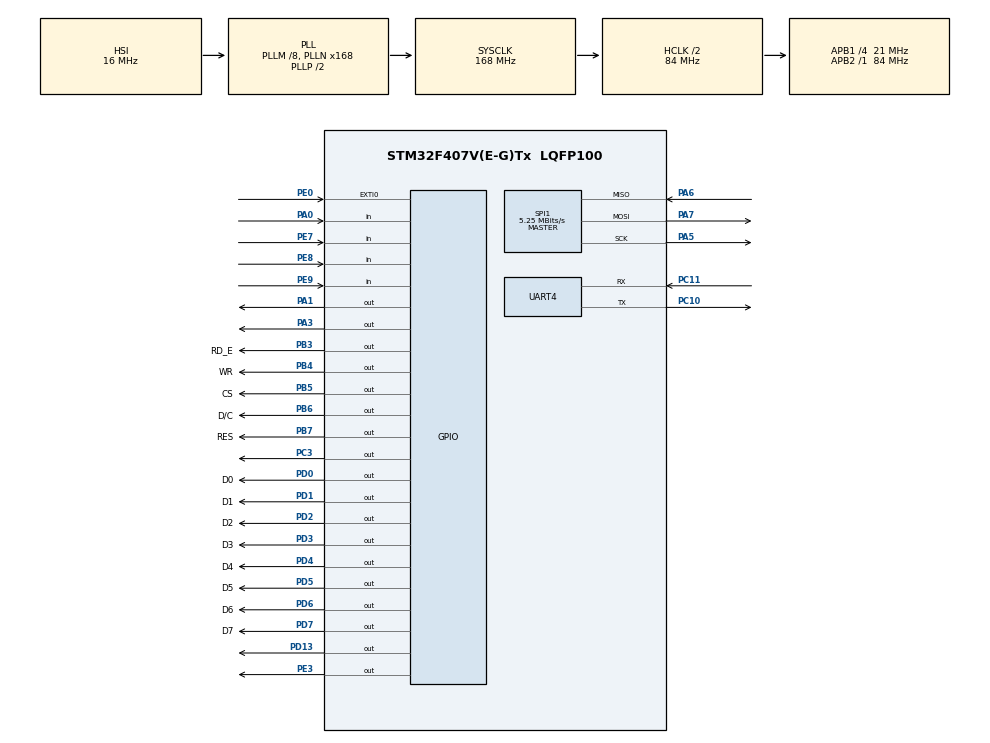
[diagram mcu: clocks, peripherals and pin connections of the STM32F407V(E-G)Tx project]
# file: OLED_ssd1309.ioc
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Dma.Request0=SPI1_TX
Dma.Request1=SPI1_RX
Dma.SPI1_RX.1.Direction=DMA_PERIPH_TO_MEMORY
Dma.SPI1_RX.1.FIFOMode=DMA_FIFOMODE_DISABLE
Dma.SPI1_RX.1.Instance=DMA2_Stream0
Dma.SPI1_RX.1.MemDataAlignment=DMA_MDATAALIGN_BYTE
Dma.SPI1_RX.1.MemInc=DMA_MINC_ENABLE
Dma.SPI1_RX.1.Mode=DMA_NORMAL
Dma.SPI1_RX.1.PeriphDataAlignment=DMA_PDATAALIGN_BYTE
Dma.SPI1_RX.1.PeriphInc=DMA_PINC_DISABLE
Dma.SPI1_RX.1.Priority=DMA_PRIORITY_LOW
Dma.SPI1_TX.0.Direction=DMA_MEMORY_TO_PERIPH
Dma.SPI1_TX.0.FIFOMode=DMA_FIFOMODE_DISABLE
Dma.SPI1_TX.0.Instance=DMA2_Stream3
Dma.SPI1_TX.0.MemDataAlignment=DMA_MDATAALIGN_BYTE
Dma.SPI1_TX.0.MemInc=DMA_MINC_ENABLE
Dma.SPI1_TX.0.Mode=DMA_NORMAL
Dma.SPI1_TX.0.PeriphDataAlignment=DMA_PDATAALIGN_BYTE
Dma.SPI1_TX.0.PeriphInc=DMA_PINC_DISABLE
Dma.SPI1_TX.0.Priority=DMA_PRIORITY_LOW
Mcu.Family=STM32F4
Mcu.Name=STM32F407V(E-G)Tx
Mcu.Package=LQFP100
NVIC.DMA2_Stream0_IRQn=true\:0\:0\:false\:false\:true\:false\:true
NVIC.DMA2_Stream3_IRQn=true\:0\:0\:false\:false\:true\:false\:true
NVIC.EXTI0_IRQn=true\:0\:0\:false\:false\:true\:true\:true
NVIC.PriorityGroup=NVIC_PRIORITYGROUP_4
NVIC.TIM6_DAC_IRQn=true\:0\:0\:false\:false\:true\:true\:true
PA0-WKUP.GPIO_PuPd=GPIO_PULLDOWN
PA0-WKUP.Signal=GPIO_Input
PA1.Signal=GPIO_Output
PA13.Mode=Serial_Wire
PA13.Signal=SYS_JTMS-SWDIO
PA14.Mode=Serial_Wire
PA14.Signal=SYS_JTCK-SWCLK
PA3.Signal=GPIO_Output
PA5.Mode=Full_Duplex_Master
PA5.Signal=SPI1_SCK
PA6.Mode=Full_Duplex_Master
PA6.Signal=SPI1_MISO
PA7.Mode=Full_Duplex_Master
PA7.Signal=SPI1_MOSI
PB3.GPIO_Label=RD_E
PB3.GPIO_Speed=GPIO_SPEED_FREQ_VERY_HIGH
PB3.PinState=GPIO_PIN_SET
PB3.Signal=GPIO_Output
PB4.GPIO_Label=WR
PB4.GPIO_Speed=GPIO_SPEED_FREQ_VERY_HIGH
PB4.PinState=GPIO_PIN_SET
PB4.Signal=GPIO_Output
PB5.GPIO_Label=CS
PB5.GPIO_PuPd=GPIO_NOPULL
PB5.GPIO_Speed=GPIO_SPEED_FREQ_VERY_HIGH
PB5.PinState=GPIO_PIN_SET
PB5.Signal=GPIO_Output
PB6.GPIO_Label=D/C
PB6.GPIO_Speed=GPIO_SPEED_FREQ_VERY_HIGH
PB6.PinState=GPIO_PIN_SET
PB6.Signal=GPIO_Output
PB7.GPIO_Label=RES
PB7.GPIO_Speed=GPIO_SPEED_FREQ_VERY_HIGH
PB7.PinState=GPIO_PIN_SET
PB7.Signal=GPIO_Output
PC10.Mode=Asynchronous
PC10.Signal=UART4_TX
PC11.Mode=Asynchronous
PC11.Signal=UART4_RX
PC3.Signal=GPIO_Output
PD0.GPIO_Label=D0
PD0.GPIO_ModeDefaultOutputPP=GPIO_MODE_OUTPUT_PP
PD0.GPIO_PuPd=GPIO_NOPULL
PD0.GPIO_Speed=GPIO_SPEED_FREQ_VERY_HIGH
PD0.PinState=GPIO_PIN_SET
PD0.Signal=GPIO_Output
PD1.GPIO_Label=D1
PD1.GPIO_Speed=GPIO_SPEED_FREQ_VERY_HIGH
PD1.PinState=GPIO_PIN_SET
PD1.Signal=GPIO_Output
PD13.Signal=GPIO_Output
PD2.GPIO_Label=D2
PD2.GPIO_Speed=GPIO_SPEED_FREQ_VERY_HIGH
PD2.PinState=GPIO_PIN_SET
PD2.Signal=GPIO_Output
PD3.GPIO_Label=D3
PD3.GPIO_Speed=GPIO_SPEED_FREQ_VERY_HIGH
PD3.PinState=GPIO_PIN_SET
PD3.Signal=GPIO_Output
PD4.GPIO_Label=D4
PD4.GPIO_Speed=GPIO_SPEED_FREQ_VERY_HIGH
PD4.PinState=GPIO_PIN_SET
PD4.Signal=GPIO_Output
PD5.GPIO_Label=D5
PD5.GPIO_Speed=GPIO_SPEED_FREQ_VERY_HIGH
PD5.PinState=GPIO_PIN_SET
PD5.Signal=GPIO_Output
PD6.GPIO_Label=D6
PD6.GPIO_Speed=GPIO_SPEED_FREQ_VERY_HIGH
PD6.PinState=GPIO_PIN_SET
PD6.Signal=GPIO_Output
PD7.GPIO_Label=D7
PD7.GPIO_Speed=GPIO_SPEED_FREQ_VERY_HIGH
PD7.PinState=GPIO_PIN_SET
PD7.Signal=GPIO_Output
PE0.Signal=GPXTI0
PE3.Signal=GPIO_Output
PE7.GPIO_PuPd=GPIO_PULLDOWN
PE7.Signal=GPIO_Input
PE8.GPIO_PuPd=GPIO_PULLDOWN
PE8.Signal=GPIO_Input
PE9.GPIO_PuPd=GPIO_PULLDOWN
PE9.Signal=GPIO_Input
PH0-OSC_IN.Mode=HSE-External-Oscillator
PH0-OSC_IN.Signal=RCC_OSC_IN
PH1-OSC_OUT.Mode=HSE-External-Oscillator
PH1-OSC_OUT.Signal=RCC_OSC_OUT
ProjectManager.HeapSize=0x200
ProjectManager.StackSize=0x400
ProjectManager.TargetToolchain=STM32CubeIDE
RCC.48MHZClocksFreq_Value=84000000
RCC.AHBCLKDivider=RCC_SYSCLK_DIV2
RCC.AHBFreq_Value=84000000
RCC.APB1CLKDivider=RCC_HCLK_DIV4
RCC.APB1Freq_Value=21000000
RCC.APB1TimFreq_Value=42000000
RCC.APB2Freq_Value=84000000
RCC.APB2TimFreq_Value=84000000
RCC.CortexFreq_Value=84000000
RCC.HCLKFreq_Value=84000000
RCC.HSE_VALUE=8000000
RCC.HSI_VALUE=16000000
RCC.LSE_VALUE=32768
RCC.PLLM=8
RCC.PLLN=168
RCC.SYSCLKFreq_VALUE=168000000
RCC.SYSCLKSource=RCC_SYSCLKSOURCE_PLLCLK
RCC.VCOOutputFreq_Value=336000000
SPI1.BaudRatePrescaler=SPI_BAUDRATEPRESCALER_16
SPI1.CalculateBaudRate=5.25 MBits/s
SPI1.Direction=SPI_DIRECTION_2LINES
SPI1.Mode=SPI_MODE_MASTER
SPI1.VirtualType=VM_MASTER
TIM6.Period=10000
TIM6.Prescaler=42000
UART4.VirtualMode=Asynchronous
VP_RTC_VS_RTC_Activate.Mode=RTC_Enabled
VP_RTC_VS_RTC_Calendar.Mode=RTC_Calendar
VP_TIM6_VS_ClockSourceINT.Mode=Enable_Timer
board=custom

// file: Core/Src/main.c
/* USER CODE BEGIN Header */
/**
  ******************************************************************************
  * @file           : main.c
  * @brief          : Main program body
  ******************************************************************************
  * @attention
  *
  * Copyright (c) 2022 STMicroelectronics.
  * All rights reserved.
  *
  * This software is licensed under terms that can be found in the LICENSE file
  * in the root directory of this software component.
  * If no LICENSE file comes with this software, it is provided AS-IS.
  *
  ******************************************************************************
  */
/* USER CODE END Header */
#include "main.h"

/* USER CODE BEGIN Includes */
#include "string.h"
#include "stdio.h"
#include "font_Times_New_Roman.h"
#include "ssd_1309.h"

#include "menu1.h"
#include "MY_LIS3DSH.h"
#include "printf.h"
//#include "menu.h"
/* USER CODE END Includes */

RTC_HandleTypeDef hrtc;

SPI_HandleTypeDef hspi1;
DMA_HandleTypeDef hdma_spi1_tx;
DMA_HandleTypeDef hdma_spi1_rx;

TIM_HandleTypeDef htim6;

UART_HandleTypeDef huart4;

void SystemClock_Config(void);
static void MX_GPIO_Init(void);
static void MX_RTC_Init(void);
static void MX_TIM6_Init(void);
static void MX_SPI1_Init(void);
static void MX_DMA_Init(void);
static void MX_UART4_Init(void);

int main(void)
{

  /* MCU Configuration--------------------------------------------------------*/

  /* Reset of all peripherals, Initializes the Flash interface and the Systick. */
  HAL_Init();

  /* Configure the system clock */
  SystemClock_Config();

  /* Initialize all configured peripherals */
  MX_GPIO_Init();
  MX_RTC_Init();
  MX_TIM6_Init();
  MX_SPI1_Init();
  MX_DMA_Init();
  MX_UART4_Init();
  /* USER CODE BEGIN 2 */

  SSD1309_init();
  SSD1309_Clear();
  SSD1309_UpdateScreen();
  /* USER CODE END 2 */

  /* Infinite loop */
  /* USER CODE BEGIN WHILE */

  while (1)
{
	  menu_display();
	  tick_ms();
    /* USER CODE END WHILE */

  }
}

void SystemClock_Config(void)
{
  RCC_OscInitTypeDef RCC_OscInitStruct = {0};
  RCC_ClkInitTypeDef RCC_ClkInitStruct = {0};

  /** Configure the main internal regulator output voltage
  */
  __HAL_RCC_PWR_CLK_ENABLE();
  __HAL_PWR_VOLTAGESCALING_CONFIG(PWR_REGULATOR_VOLTAGE_SCALE1);
  /** Initializes the RCC Oscillators according to the specified parameters
  * in the RCC_OscInitTypeDef structure.
  */
  RCC_OscInitStruct.OscillatorType = RCC_OSCILLATORTYPE_HSI|RCC_OSCILLATORTYPE_LSI;
  RCC_OscInitStruct.HSIState = RCC_HSI_ON;
  RCC_OscInitStruct.HSICalibrationValue = RCC_HSICALIBRATION_DEFAULT;
  RCC_OscInitStruct.LSIState = RCC_LSI_ON;
  RCC_OscInitStruct.PLL.PLLState = RCC_PLL_ON;
  RCC_OscInitStruct.PLL.PLLSource = RCC_PLLSOURCE_HSI;
  RCC_OscInitStruct.PLL.PLLM = 8;
  RCC_OscInitStruct.PLL.PLLN = 168;
  RCC_OscInitStruct.PLL.PLLP = RCC_PLLP_DIV2;
  RCC_OscInitStruct.PLL.PLLQ = 4;
  if (HAL_RCC_OscConfig(&RCC_OscInitStruct) != HAL_OK)
  {
    Error_Handler();
  }
  /** Initializes the CPU, AHB and APB buses clocks
  */
  RCC_ClkInitStruct.ClockType = RCC_CLOCKTYPE_HCLK|RCC_CLOCKTYPE_SYSCLK
                              |RCC_CLOCKTYPE_PCLK1|RCC_CLOCKTYPE_PCLK2;
  RCC_ClkInitStruct.SYSCLKSource = RCC_SYSCLKSOURCE_PLLCLK;
  RCC_ClkInitStruct.AHBCLKDivider = RCC_SYSCLK_DIV2;
  RCC_ClkInitStruct.APB1CLKDivider = RCC_HCLK_DIV4;
  RCC_ClkInitStruct.APB2CLKDivider = RCC_HCLK_DIV1;

  if (HAL_RCC_ClockConfig(&RCC_ClkInitStruct, FLASH_LATENCY_2) != HAL_OK)
  {
    Error_Handler();
  }
}

static void MX_RTC_Init(void)
{

  RTC_TimeTypeDef sTime = {0};
  RTC_DateTypeDef sDate = {0};

  /** Initialize RTC Only
  */
  hrtc.Instance = RTC;
  hrtc.Init.HourFormat = RTC_HOURFORMAT_24;
  hrtc.Init.AsynchPrediv = 127;
  hrtc.Init.SynchPrediv = 255;
  hrtc.Init.OutPut = RTC_OUTPUT_DISABLE;
  hrtc.Init.OutPutPolarity = RTC_OUTPUT_POLARITY_HIGH;
  hrtc.Init.OutPutType = RTC_OUTPUT_TYPE_OPENDRAIN;
  if (HAL_RTC_Init(&hrtc) != HAL_OK)
  {
    Error_Handler();
  }

  /** Initialize RTC and set the Time and Date
  */
  sTime.Hours = 0x0;
  sTime.Minutes = 0x0;
  sTime.Seconds = 0x0;
  sTime.DayLightSaving = RTC_DAYLIGHTSAVING_NONE;
  sTime.StoreOperation = RTC_STOREOPERATION_RESET;
  if (HAL_RTC_SetTime(&hrtc, &sTime, RTC_FORMAT_BCD) != HAL_OK)
  {
    Error_Handler();
  }
  sDate.WeekDay = RTC_WEEKDAY_MONDAY;
  sDate.Month = RTC_MONTH_JANUARY;
  sDate.Date = 0x1;
  sDate.Year = 0x0;

  if (HAL_RTC_SetDate(&hrtc, &sDate, RTC_FORMAT_BCD) != HAL_OK)
  {
    Error_Handler();
  }

}

static void MX_SPI1_Init(void)
{

  /* SPI1 parameter configuration*/
  hspi1.Instance = SPI1;
  hspi1.Init.Mode = SPI_MODE_MASTER;
  hspi1.Init.Direction = SPI_DIRECTION_2LINES;
  hspi1.Init.DataSize = SPI_DATASIZE_8BIT;
  hspi1.Init.CLKPolarity = SPI_POLARITY_LOW;
  hspi1.Init.CLKPhase = SPI_PHASE_1EDGE;
  hspi1.Init.NSS = SPI_NSS_SOFT;
  hspi1.Init.BaudRatePrescaler = SPI_BAUDRATEPRESCALER_16;
  hspi1.Init.FirstBit = SPI_FIRSTBIT_MSB;
  hspi1.Init.TIMode = SPI_TIMODE_DISABLE;
  hspi1.Init.CRCCalculation = SPI_CRCCALCULATION_DISABLE;
  hspi1.Init.CRCPolynomial = 10;
  if (HAL_SPI_Init(&hspi1) != HAL_OK)
  {
    Error_Handler();
  }

}

static void MX_TIM6_Init(void)
{

  TIM_MasterConfigTypeDef sMasterConfig = {0};

  htim6.Instance = TIM6;
  htim6.Init.Prescaler = 4200;
  htim6.Init.CounterMode = TIM_COUNTERMODE_UP;
  htim6.Init.Period = 50000;
  htim6.Init.AutoReloadPreload = TIM_AUTORELOAD_PRELOAD_DISABLE;
  if (HAL_TIM_Base_Init(&htim6) != HAL_OK)
  {
    Error_Handler();
  }
  sMasterConfig.MasterOutputTrigger = TIM_TRGO_RESET;
  sMasterConfig.MasterSlaveMode = TIM_MASTERSLAVEMODE_DISABLE;
  if (HAL_TIMEx_MasterConfigSynchronization(&htim6, &sMasterConfig) != HAL_OK)
  {
    Error_Handler();
  }

}

static void MX_UART4_Init(void)
{

  huart4.Instance = UART4;
  huart4.Init.BaudRate = 115200;
  huart4.Init.WordLength = UART_WORDLENGTH_8B;
  huart4.Init.StopBits = UART_STOPBITS_1;
  huart4.Init.Parity = UART_PARITY_NONE;
  huart4.Init.Mode = UART_MODE_TX_RX;
  huart4.Init.HwFlowCtl = UART_HWCONTROL_NONE;
  huart4.Init.OverSampling = UART_OVERSAMPLING_16;
  if (HAL_UART_Init(&huart4) != HAL_OK)
  {
    Error_Handler();
  }

}

static void MX_DMA_Init(void)
{

  /* DMA controller clock enable */
  __HAL_RCC_DMA2_CLK_ENABLE();

  /* DMA interrupt init */
  /* DMA2_Stream0_IRQn interrupt configuration */
  HAL_NVIC_SetPriority(DMA2_Stream0_IRQn, 0, 0);
  HAL_NVIC_EnableIRQ(DMA2_Stream0_IRQn);
  /* DMA2_Stream3_IRQn interrupt configuration */
  HAL_NVIC_SetPriority(DMA2_Stream3_IRQn, 0, 0);
  HAL_NVIC_EnableIRQ(DMA2_Stream3_IRQn);

}

static void MX_GPIO_Init(void)
{
  GPIO_InitTypeDef GPIO_InitStruct = {0};

  /* GPIO Ports Clock Enable */
  __HAL_RCC_GPIOE_CLK_ENABLE();
  __HAL_RCC_GPIOH_CLK_ENABLE();
  __HAL_RCC_GPIOC_CLK_ENABLE();
  __HAL_RCC_GPIOA_CLK_ENABLE();
  __HAL_RCC_GPIOD_CLK_ENABLE();
  __HAL_RCC_GPIOB_CLK_ENABLE();

  /*Configure GPIO pin Output Level */
  HAL_GPIO_WritePin(GPIOE, GPIO_PIN_3, GPIO_PIN_RESET);

  /*Configure GPIO pin Output Level */
  HAL_GPIO_WritePin(GPIOC, GPIO_PIN_3, GPIO_PIN_RESET);

  /*Configure GPIO pin Output Level */
  HAL_GPIO_WritePin(GPIOA, GPIO_PIN_1|GPIO_PIN_3, GPIO_PIN_RESET);

  /*Configure GPIO pin Output Level */
  HAL_GPIO_WritePin(GPIOD, GPIO_PIN_13, GPIO_PIN_RESET);

  /*Configure GPIO pin Output Level */
  HAL_GPIO_WritePin(GPIOD, D0_Pin|D1_Pin|D2_Pin|D3_Pin
                          |D4_Pin|D5_Pin|D6_Pin|D7_Pin, GPIO_PIN_SET);

  /*Configure GPIO pin Output Level */
  HAL_GPIO_WritePin(GPIOB, RD_E_Pin|WR_Pin|CS_Pin|D_C_Pin
                          |RES_Pin, GPIO_PIN_SET);

  /*Configure GPIO pin : PE3 */
  GPIO_InitStruct.Pin = GPIO_PIN_3;
  GPIO_InitStruct.Mode = GPIO_MODE_OUTPUT_PP;
  GPIO_InitStruct.Pull = GPIO_NOPULL;
  GPIO_InitStruct.Speed = GPIO_SPEED_FREQ_LOW;
  HAL_GPIO_Init(GPIOE, &GPIO_InitStruct);

  /*Configure GPIO pin : PC3 */
  GPIO_InitStruct.Pin = GPIO_PIN_3;
  GPIO_InitStruct.Mode = GPIO_MODE_OUTPUT_PP;
  GPIO_InitStruct.Pull = GPIO_NOPULL;
  GPIO_InitStruct.Speed = GPIO_SPEED_FREQ_LOW;
  HAL_GPIO_Init(GPIOC, &GPIO_InitStruct);

  /*Configure GPIO pin : PA0 */
  GPIO_InitStruct.Pin = GPIO_PIN_0;
  GPIO_InitStruct.Mode = GPIO_MODE_INPUT;
  GPIO_InitStruct.Pull = GPIO_PULLDOWN;
  HAL_GPIO_Init(GPIOA, &GPIO_InitStruct);

  /*Configure GPIO pins : PA1 PA3 */
  GPIO_InitStruct.Pin = GPIO_PIN_1|GPIO_PIN_3;
  GPIO_InitStruct.Mode = GPIO_MODE_OUTPUT_PP;
  GPIO_InitStruct.Pull = GPIO_NOPULL;
  GPIO_InitStruct.Speed = GPIO_SPEED_FREQ_LOW;
  HAL_GPIO_Init(GPIOA, &GPIO_InitStruct);

  /*Configure GPIO pins : PE7 PE8 PE9 */
  GPIO_InitStruct.Pin = GPIO_PIN_7|GPIO_PIN_8|GPIO_PIN_9;
  GPIO_InitStruct.Mode = GPIO_MODE_INPUT;
  GPIO_InitStruct.Pull = GPIO_PULLDOWN;
  HAL_GPIO_Init(GPIOE, &GPIO_InitStruct);

  /*Configure GPIO pin : PD13 */
  GPIO_InitStruct.Pin = GPIO_PIN_13;
  GPIO_InitStruct.Mode = GPIO_MODE_OUTPUT_PP;
  GPIO_InitStruct.Pull = GPIO_NOPULL;
  GPIO_InitStruct.Speed = GPIO_SPEED_FREQ_LOW;
  HAL_GPIO_Init(GPIOD, &GPIO_InitStruct);

  /*Configure GPIO pins : D0_Pin D1_Pin D2_Pin D3_Pin
                           D4_Pin D5_Pin D6_Pin D7_Pin */
  GPIO_InitStruct.Pin = D0_Pin|D1_Pin|D2_Pin|D3_Pin
                          |D4_Pin|D5_Pin|D6_Pin|D7_Pin;
  GPIO_InitStruct.Mode = GPIO_MODE_OUTPUT_PP;
  GPIO_InitStruct.Pull = GPIO_NOPULL;
  GPIO_InitStruct.Speed = GPIO_SPEED_FREQ_VERY_HIGH;
  HAL_GPIO_Init(GPIOD, &GPIO_InitStruct);

  /*Configure GPIO pins : RD_E_Pin WR_Pin CS_Pin D_C_Pin
                           RES_Pin */
  GPIO_InitStruct.Pin = RD_E_Pin|WR_Pin|CS_Pin|D_C_Pin
                          |RES_Pin;
  GPIO_InitStruct.Mode = GPIO_MODE_OUTPUT_PP;
  GPIO_InitStruct.Pull = GPIO_NOPULL;
  GPIO_InitStruct.Speed = GPIO_SPEED_FREQ_VERY_HIGH;
  HAL_GPIO_Init(GPIOB, &GPIO_InitStruct);

  /*Configure GPIO pin : PE0 */
  GPIO_InitStruct.Pin = GPIO_PIN_0;
  GPIO_InitStruct.Mode = GPIO_MODE_IT_RISING;
  GPIO_InitStruct.Pull = GPIO_NOPULL;
  HAL_GPIO_Init(GPIOE, &GPIO_InitStruct);

  /* EXTI interrupt init*/
  HAL_NVIC_SetPriority(EXTI0_IRQn, 0, 0);
  HAL_NVIC_EnableIRQ(EXTI0_IRQn);

}

/* USER CODE BEGIN 4 */
 /*void HAL_SPI_RxCpltCallback(SPI_HandleTypeDef *hspi)
{
		flag_rx = 1;
}*/

void HAL_GPIO_EXTI_Callback(uint16_t GPIO_Pin)
   {
     /* Prevent unused argument(s) compilation warning */
     //UNUSED(GPIO_Pin);
     /* NOTE: This function Should not be modified, when the callback is needed,
              the HAL_GPIO_EXTI_Callback could be implemented in the user file
      */
   }
/* USER CODE END 4 */

void Error_Handler(void)
{
  __disable_irq();
  while (1)
  {
  }
}
